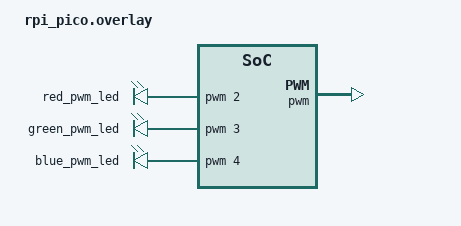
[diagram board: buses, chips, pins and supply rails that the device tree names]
/*
 * SPDX-License-Identifier: Apache-2.0
 */

/{
	aliases {
		red-pwm-led = &red_pwm_led;
		green-pwm-led = &green_pwm_led;
		blue-pwm-led = &blue_pwm_led;
	};
	pwmleds {
		compatible = "pwm-leds";

		red_pwm_led: red_pwm_led {
			pwms = <&pwm 2 PWM_MSEC(20) PWM_POLARITY_NORMAL>;
		};
		green_pwm_led: green_pwm_led {
			pwms = <&pwm 3 PWM_MSEC(20) PWM_POLARITY_NORMAL>;
		};
		blue_pwm_led: blue_pwm_led {
			pwms = <&pwm 4 PWM_MSEC(20) PWM_POLARITY_NORMAL>;
		};
	};
};

&pwm {
	status = "okay";
	divider-frac-1 = <15>;
	divider-int-1 = <255>;
	divider-frac-2 = <15>;
	divider-int-2 = <255>;
};

&pwm_ch4b_default {
	group2 {
		pinmux = <PWM_1A_P2>, <PWM_1B_P3>, <PWM_2A_P4>;
	};
};

